# haltium_bbpr register map
Vendor: Nordic Semiconductor; Series: nRFHaltium; File version: 1
Registers are 32-bit, read-write, reset 0x0 unless marked. A register's access mark holds for its fields unless they carry their own. Offsets are from the block's base; [hi:lo] are bit positions; lines under a group give offsets from that group; 'fields as' and 'values as' point back to an identical list.

## GLOBAL_SERIOBOX0_NS — SerIOBox 0
Base 0x4F8E5000
Same registers: GLOBAL_SERIOBOX1_NS 0x4F8E8000, GLOBAL_SERIOBOX0_S 0x5F8E5000, GLOBAL_SERIOBOX1_S 0x5F8E8000
0x10C EVENTS_TXBUFFERREADY — TX buffer is ready
  [0] EVENTS_TXBUFFERREADY
    0=NotGenerated (Event not generated); 1=Generated (Event generated)
0x114 EVENTS_DMAENDTX — Ended TX over DMA
  [0] EVENTS_DMAENDTX
    values as EVENTS_TXBUFFERREADY.EVENTS_TXBUFFERREADY
0x12C EVENTS_ADDRESSMATCH — Address match occured
  [0] EVENTS_ADDRESSMATCH
    values as EVENTS_TXBUFFERREADY.EVENTS_TXBUFFERREADY
0x130 EVENTS_RECEIVEDACK — Received ACK
  [0] EVENTS_RECEIVEDACK
    values as EVENTS_TXBUFFERREADY.EVENTS_TXBUFFERREADY
0x13C EVENTS_READYRX — RX ready
  [0] EVENTS_READYRX
    values as EVENTS_TXBUFFERREADY.EVENTS_TXBUFFERREADY
0x140 EVENTS_READYTX — TX ready
  [0] EVENTS_READYTX
    values as EVENTS_TXBUFFERREADY.EVENTS_TXBUFFERREADY
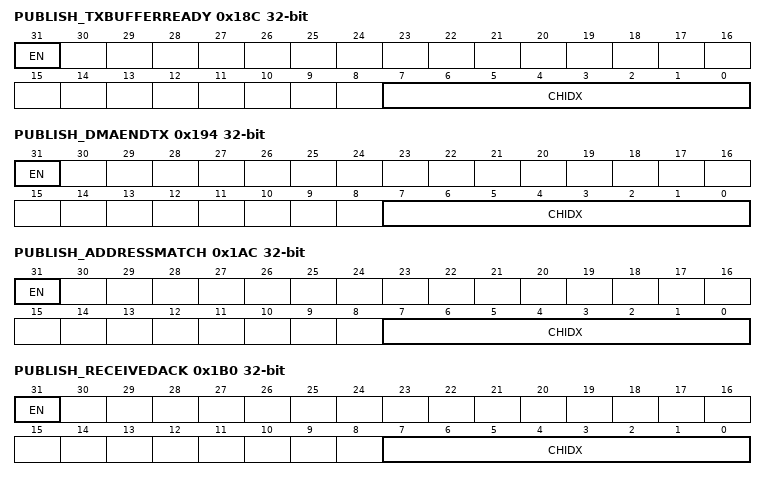
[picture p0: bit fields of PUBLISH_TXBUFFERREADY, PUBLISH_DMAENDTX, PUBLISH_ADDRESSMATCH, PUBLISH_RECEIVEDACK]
0x18C PUBLISH_TXBUFFERREADY — Publish configuration for event TXBUFFERREADY
  [31] EN
    0=Disabled (Disable publishing); 1=Enabled (Enable publishing)
  [7:0] CHIDX — DPPI channel that event TXBUFFERREADY will publish to
0x194 PUBLISH_DMAENDTX — Publish configuration for event DMAENDTX
  [31] EN
    values as PUBLISH_TXBUFFERREADY.EN
  [7:0] CHIDX — DPPI channel that event DMAENDTX will publish to
0x1AC PUBLISH_ADDRESSMATCH — Publish configuration for event ADDRESSMATCH
  [31] EN
    values as PUBLISH_TXBUFFERREADY.EN
  [7:0] CHIDX — DPPI channel that event ADDRESSMATCH will publish to
0x1B0 PUBLISH_RECEIVEDACK — Publish configuration for event RECEIVEDACK
  [31] EN
    values as PUBLISH_TXBUFFERREADY.EN
  [7:0] CHIDX — DPPI channel that event RECEIVEDACK will publish to
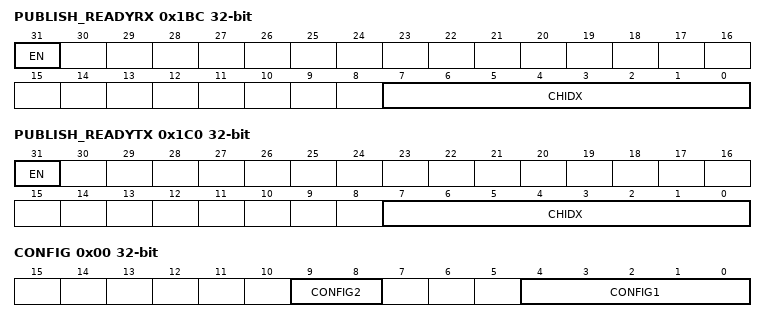
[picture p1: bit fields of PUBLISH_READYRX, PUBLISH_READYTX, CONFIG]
0x1BC PUBLISH_READYRX — Publish configuration for event READYRX
  [31] EN
    values as PUBLISH_TXBUFFERREADY.EN
  [7:0] CHIDX — DPPI channel that event READYRX will publish to
0x1C0 PUBLISH_READYTX — Publish configuration for event READYTX
  [31] EN
    values as PUBLISH_TXBUFFERREADY.EN
  [7:0] CHIDX — DPPI channel that event READYTX will publish to
0x400 WIRE2 group — Unspecified
  0xC0 STATUS — Wire2 status reg
    [0] STATUS
  0x180 ENABLE — TWIM enable
    [0] ENABLE
      0=Disabled (Unspecified); 1=Enabled (Unspecified)
  0x184 CONFIG — TWIM config (seems not in use when Wire2 configured as master)
    [5:0] CONFIG
0x518 DATA group (alternate view of WIRE2) — Unspecified
  0x00 RXD ro — SerIOBox RX data
    [7:0] DATA
  0x04 TXD — SerIOBox TX data
    [7:0] Data
0x528 BRG group (alternate view of WIRE2) — Unspecified
  0x00 CONFIG — BRG config
    [9:8] CONFIG2, [4:0] CONFIG1
0x550 SPI group (alternate view of WIRE2) — Unspecified
  0x00 STARTSTOP reset 0x2 — Unused register
    [1:0] STARTSTOP
  0x14 ENABLE — SPI enable
    [0] ENABLE
      0=Disabled (Unspecified); 1=Enabled (Unspecified)
0x560 UART group (alternate view of WIRE2) — Unspecified
  0x00 ENABLE — Uart enable
    [0] ENABLE
      0=Disabled (Unspecified); 1=Enabled (Unspecified)
  0x04 RXENABLE — Uart RX enable
    [0] RXENABLE
      0=Disabled (Unspecified); 1=Enabled (Unspecified)
  0x08 TXENABLE — Uart TX enable
    [0] TXENABLE
      0=Disabled (Unspecified); 1=Enabled (Unspecified)
0x590 TWIS group (alternate view of WIRE2) — Unspecified
  0x00 ENABLE — TWIS enable
    [0] ENABLE
0x5CC DMACHANNEL group (alternate view of WIRE2) — Unspecified
  0x464 ENABLE group — Unspecified
    0x00 RX — RX DCP enable
      [0] ENABLE
        0=Disabled (Unspecified); 1=Enabled (Unspecified)
    0x04 TX — TX DCP enable
      [0] ENABLE
        0=Disabled (Unspecified); 1=Enabled (Unspecified)
  0x46C TXDATASIZE ro — TX samples transmitted (same as TXD.AMOUNT)
    [12:0] DATASIZE
0xD00 PCGC_SET_POWER_CONSUMPTION_BASE — PcgcMaster power consumpion registers
  [0] PCGC_SET_POWER_CONSUMPTION_BASE
